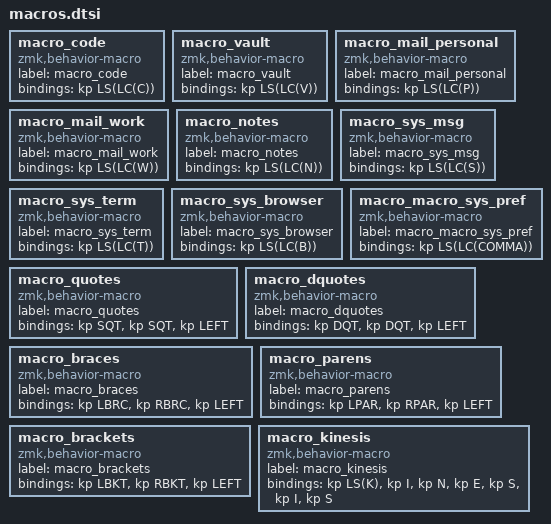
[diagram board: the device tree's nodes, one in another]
macro_code: macro_code{
compatible = "zmk,behavior-macro";
label = "macro_code";
#binding-cells = <0>;
bindings = <&kp LS(LC(C))>;
};
macro_vault: macro_vault{
compatible = "zmk,behavior-macro";
label = "macro_vault";
#binding-cells = <0>;
bindings = <&kp LS(LC(V))>;
};
macro_mail_personal: macro_mail_personal{
compatible = "zmk,behavior-macro";
label = "macro_mail_personal";
#binding-cells = <0>;
bindings = <&kp LS(LC(P))>;
};
macro_mail_work: macro_mail_work{
compatible = "zmk,behavior-macro";
label = "macro_mail_work";
#binding-cells = <0>;
bindings = <&kp LS(LC(W))>;
};
macro_notes: macro_notes{
compatible = "zmk,behavior-macro";
label = "macro_notes";
#binding-cells = <0>;
bindings = <&kp LS(LC(N))>;
};
macro_sys_msg: macro_sys_msg{
compatible = "zmk,behavior-macro";
label = "macro_sys_msg";
#binding-cells = <0>;
bindings = <&kp LS(LC(S))>;
};
macro_sys_term: macro_sys_term{
compatible = "zmk,behavior-macro";
label = "macro_sys_term";
#binding-cells = <0>;
bindings = <&kp LS(LC(T))>;
};
macro_sys_browser: macro_sys_browser{
compatible = "zmk,behavior-macro";
label = "macro_sys_browser";
#binding-cells = <0>;
bindings = <&kp LS(LC(B))>;
};
macro_macro_sys_pref: macro_macro_sys_pref{
compatible = "zmk,behavior-macro";
label = "macro_macro_sys_pref";
#binding-cells = <0>;
bindings = <&kp LS(LC(COMMA))>;
};
macro_quotes: macro_quotes{
compatible = "zmk,behavior-macro";
label = "macro_quotes";
#binding-cells = <0>;
bindings = <&kp SQT>, <&kp SQT>, <&kp LEFT>;
};
macro_dquotes: macro_dquotes{
compatible = "zmk,behavior-macro";
label = "macro_dquotes";
#binding-cells = <0>;
bindings = <&kp DQT>, <&kp DQT>, <&kp LEFT>;
};
macro_braces: macro_braces{
compatible = "zmk,behavior-macro";
label = "macro_braces";
#binding-cells = <0>;
bindings = <&kp LBRC>, <&kp RBRC>, <&kp LEFT>;
};
macro_parens: macro_parens{
compatible = "zmk,behavior-macro";
label = "macro_parens";
#binding-cells = <0>;
bindings = <&kp LPAR>, <&kp RPAR>, <&kp LEFT>;
};
macro_brackets: macro_brackets{
compatible = "zmk,behavior-macro";
label = "macro_brackets";
#binding-cells = <0>;
bindings = <&kp LBKT>, <&kp RBKT>, <&kp LEFT>;
};
macro_kinesis: macro_kinesis{
compatible = "zmk,behavior-macro";
label = "macro_kinesis";
#binding-cells = <0>;
bindings = <&kp LS(K)>, <&kp I>, <&kp N>, <&kp E>, <&kp S>, <&kp I>, <&kp S>;
};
